# STM32WL33 register map
File version: 1.0
CPU: CM0+ r0p0, little endian, MPU, no FPU, 4 interrupt priority bits
Registers are 32-bit, read-write, reset 0x0 unless marked. A register's access mark holds for its fields unless they carry their own. Offsets are from the block's base; [hi:lo] are bit positions; {n}, {i} and the like mark numbered series.

## IWDG
Base 0x40003000
0x00 KR — IWDG_KR register
  [15:0] KEY wo — Key value. Software can only write these bits. Reading returns the reset value. These bits must be written by software at regular intervals with the key value 0xAAAA, otherwise the watchdog generates a reset when the counter reaches 0. Writing the key value 0x5555 to enables access to the IWDG_PR, IWDG_RLR and IWDG_WINR registers. Writing the key value CCCCh starts the watchdog
0x04 PR — IWDG_PR register
  [2:0] PR — Prescaler divider. Set and reset by software. These bits are write access protected. They are written by software to select the prescaler divider feeding the counter clock. PVU bit of IWDG_SR must be reset in order to be able to change the prescaler divider. 000: divider/4 001: divider/8 010: divider/16 011: divider/32 100: divider/64 101: divider/128 110: divider/256 111: divider/256
0x08 RLR reset 0xFFF — IWDG_RLR register
  [11:0] RL — Watchdog counter reload value. Set and reset by software. These bits are write access protected. They are written by software to define the value to be loaded in the watchdog counter each time the value 0xAAAA is written in the IWDG_KR register. The watchdog counter counts down from this value. The timeout period is a function of this value and the clock prescaler. The RVU bit in the IWDG_SR register must be reset in order to be able to change the reload value.
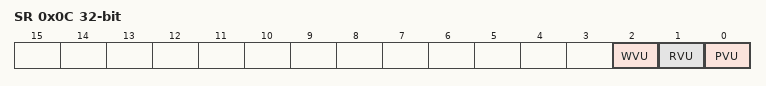
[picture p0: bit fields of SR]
0x0C SR ro — IWDG_SR register
  [2] WVU — Watchdog counter window value update. Read only bit. This bit is set by hardware to indicate that an update of the window value is ongoing. It is reset by hardware when the reload value update operation is completed in the VDD voltage domain (takes up to 5 RC 40 kHz cycles). Window value can be updated only when WVU bit is reset. This bit is generated only if generic 'window' = 1
  [1] RVU — Watchdog counter reload value update. Read only bit. This bit is set by hardware to indicate that an update of the reload value is ongoing. It is reset by hardware when the reload value update operation is completed in the VDD voltage domain (takes up to 5 RC 40 kHz cycles). Reload value can be updated only when RVU bit is reset
  [0] PVU — Watchdog prescaler value update. Read only bit. This bit is set by hardware to indicate that an update of the prescaler value is ongoing. It is reset by hardware when the prescaler update operation is completed in the VDD voltage domain (takes up to 5 RC 40 kHz cycles). Prescaler value can be updated only when PVU bit is reset
0x10 WINR reset 0xFFF — IWDG_WINR register
  [11:0] WIN — Watchdog counter window value. Set and reset by software. These bits are write access protected. These bits contain the high limit of the window value to be compared to the downcounter. To prevent a reset, the downcounter must be reloaded when its value is lower than the window register value and greater than 0x0 The WVU bit in the IWDG_SR register must be reset in order to be able to change the reload value.

## LCD
Base 0x40007000
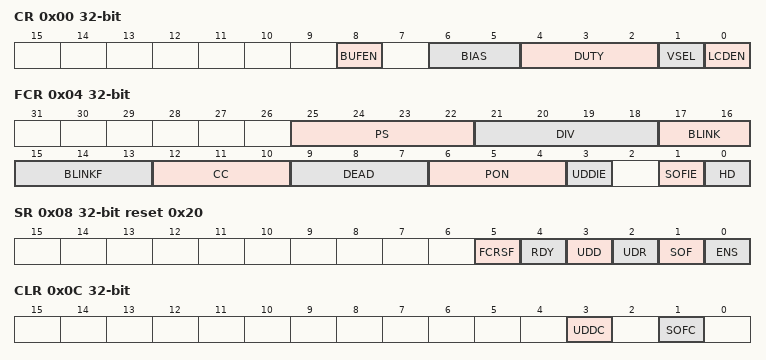
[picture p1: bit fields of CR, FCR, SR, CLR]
0x00 CR — LCD_CR register
  [8] BUFEN — Voltage output buffer enable
  [6:5] BIAS — Bias selector
  [4:2] DUTY — Duty selection
  [1] VSEL — Voltage source selection
  [0] LCDEN — LCD controller enable
0x04 FCR — LCD_FCR register
  [25:22] PS — PS 16-bit prescaler
  [21:18] DIV — DIV clock divider
  [17:16] BLINK — Blink mode selection
  [15:13] BLINKF — Blink frequency selection
  [12:10] CC — Contrast control
  [9:7] DEAD — Dead time duration
  [6:4] PON — Pulse ON duration
  [3] UDDIE — Update display done interrupt enable
  [1] SOFIE — Start of frame interrupt enable
  [0] HD — High drive enable
0x08 SR ro reset 0x20 — LCD_SR register
  [5] FCRSF — LCD Frame Control Register Synchronization flag
  [4] RDY — Ready flag
  [3] UDD — Update Display Done
  [2] UDR — Update display request
  [1] SOF — Start of frame flag
  [0] ENS — LCD enabled status
0x0C CLR — LCD_CLR register
  [3] UDDC wo — Update display done clear
  [1] SOFC wo — Start of frame flag clear
{0x14+8i} RAM_COM{i} (i=0..7) — LCD_RAM_COMx register
  [15:0] SEGMENT_DATA — Each bit corresponds to one pixel of the LCD display.
